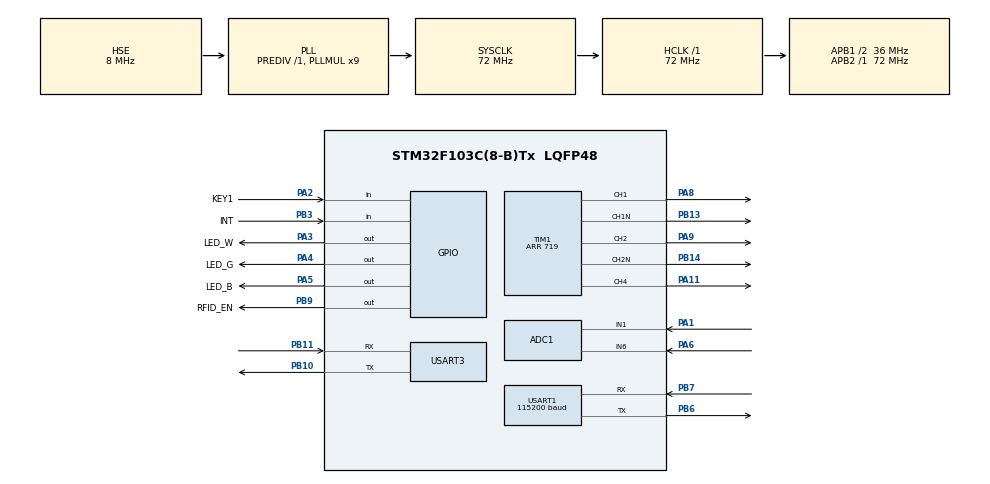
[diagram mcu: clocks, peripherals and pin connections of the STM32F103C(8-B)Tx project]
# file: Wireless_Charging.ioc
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ADC1.Channel-0\#ChannelRegularConversion=ADC_CHANNEL_1
ADC1.Channel-1\#ChannelRegularConversion=ADC_CHANNEL_6
ADC1.ContinuousConvMode=ENABLE
ADC1.NbrOfConversion=2
ADC1.NbrOfConversionFlag=1
ADC1.Rank-0\#ChannelRegularConversion=1
ADC1.Rank-1\#ChannelRegularConversion=2
ADC1.SamplingTime-0\#ChannelRegularConversion=ADC_SAMPLETIME_71CYCLES_5
ADC1.SamplingTime-1\#ChannelRegularConversion=ADC_SAMPLETIME_239CYCLES_5
ADC1.master=1
Dma.ADC1.4.Direction=DMA_PERIPH_TO_MEMORY
Dma.ADC1.4.Instance=DMA1_Channel1
Dma.ADC1.4.MemDataAlignment=DMA_MDATAALIGN_HALFWORD
Dma.ADC1.4.MemInc=DMA_MINC_ENABLE
Dma.ADC1.4.Mode=DMA_CIRCULAR
Dma.ADC1.4.PeriphDataAlignment=DMA_PDATAALIGN_HALFWORD
Dma.ADC1.4.PeriphInc=DMA_PINC_DISABLE
Dma.ADC1.4.Priority=DMA_PRIORITY_HIGH
Dma.Request0=USART1_RX
Dma.Request1=USART1_TX
Dma.Request2=USART3_TX
Dma.Request3=USART3_RX
Dma.Request4=ADC1
Dma.USART1_RX.0.Direction=DMA_PERIPH_TO_MEMORY
Dma.USART1_RX.0.Instance=DMA1_Channel5
Dma.USART1_RX.0.MemDataAlignment=DMA_MDATAALIGN_BYTE
Dma.USART1_RX.0.MemInc=DMA_MINC_ENABLE
Dma.USART1_RX.0.Mode=DMA_CIRCULAR
Dma.USART1_RX.0.PeriphDataAlignment=DMA_PDATAALIGN_BYTE
Dma.USART1_RX.0.PeriphInc=DMA_PINC_DISABLE
Dma.USART1_RX.0.Priority=DMA_PRIORITY_LOW
Dma.USART1_TX.1.Direction=DMA_MEMORY_TO_PERIPH
Dma.USART1_TX.1.Instance=DMA1_Channel4
Dma.USART1_TX.1.MemDataAlignment=DMA_MDATAALIGN_BYTE
Dma.USART1_TX.1.MemInc=DMA_MINC_ENABLE
Dma.USART1_TX.1.Mode=DMA_NORMAL
Dma.USART1_TX.1.PeriphDataAlignment=DMA_PDATAALIGN_BYTE
Dma.USART1_TX.1.PeriphInc=DMA_PINC_DISABLE
Dma.USART1_TX.1.Priority=DMA_PRIORITY_LOW
Dma.USART3_RX.3.Direction=DMA_PERIPH_TO_MEMORY
Dma.USART3_RX.3.Instance=DMA1_Channel3
Dma.USART3_RX.3.MemDataAlignment=DMA_MDATAALIGN_BYTE
Dma.USART3_RX.3.MemInc=DMA_MINC_ENABLE
Dma.USART3_RX.3.Mode=DMA_CIRCULAR
Dma.USART3_RX.3.PeriphDataAlignment=DMA_PDATAALIGN_BYTE
Dma.USART3_RX.3.PeriphInc=DMA_PINC_DISABLE
Dma.USART3_RX.3.Priority=DMA_PRIORITY_LOW
Dma.USART3_TX.2.Direction=DMA_MEMORY_TO_PERIPH
Dma.USART3_TX.2.Instance=DMA1_Channel2
Dma.USART3_TX.2.MemDataAlignment=DMA_MDATAALIGN_BYTE
Dma.USART3_TX.2.MemInc=DMA_MINC_ENABLE
Dma.USART3_TX.2.Mode=DMA_NORMAL
Dma.USART3_TX.2.PeriphDataAlignment=DMA_PDATAALIGN_BYTE
Dma.USART3_TX.2.PeriphInc=DMA_PINC_DISABLE
Dma.USART3_TX.2.Priority=DMA_PRIORITY_LOW
FREERTOS.Events01=xDataProcessEvent,Dynamic,NULL
FREERTOS.INCLUDE_xEventGroupSetBitFromISR=1
FREERTOS.Tasks01=defaultTask,8,64,StartDefaultTask,Default,NULL,Dynamic,NULL,NULL;controlTask,32,256,StartControlTask,As external,NULL,Dynamic,NULL,NULL;dataProcessTask,40,256,StartDataProcessTask,As external,NULL,Dynamic,NULL,NULL
FREERTOS.configENABLE_FPU=0
FREERTOS.configMINIMAL_STACK_SIZE=64
Mcu.Family=STM32F1
Mcu.Name=STM32F103C(8-B)Tx
Mcu.Package=LQFP48
NVIC.DMA1_Channel1_IRQn=true\:5\:0\:false\:false\:true\:true\:false\:true\:true
NVIC.DMA1_Channel2_IRQn=true\:5\:0\:false\:false\:true\:true\:false\:true\:true
NVIC.DMA1_Channel3_IRQn=true\:5\:0\:false\:false\:true\:true\:false\:true\:true
NVIC.DMA1_Channel4_IRQn=true\:5\:0\:false\:false\:true\:true\:false\:true\:true
NVIC.DMA1_Channel5_IRQn=true\:5\:0\:false\:false\:true\:true\:false\:true\:true
NVIC.PriorityGroup=NVIC_PRIORITYGROUP_4
NVIC.TIM2_IRQn=true\:15\:0\:false\:false\:true\:false\:false\:true\:true
NVIC.TIM3_IRQn=true\:5\:0\:false\:false\:true\:true\:true\:true\:true
NVIC.TIM4_IRQn=true\:5\:0\:false\:false\:true\:true\:true\:true\:true
NVIC.TimeBase=TIM2_IRQn
NVIC.TimeBaseIP=TIM2
NVIC.USART1_IRQn=true\:5\:0\:false\:false\:true\:true\:true\:true\:true
NVIC.USART3_IRQn=true\:5\:0\:false\:false\:true\:true\:true\:true\:true
PA1.Signal=ADCx_IN1
PA11.Signal=S_TIM1_CH4
PA13.Mode=Serial_Wire
PA13.Signal=SYS_JTMS-SWDIO
PA14.Mode=Serial_Wire
PA14.Signal=SYS_JTCK-SWCLK
PA2.GPIO_Label=KEY1
PA2.Signal=GPIO_Input
PA3.GPIO_Label=LED_W
PA3.Signal=GPIO_Output
PA4.GPIO_Label=LED_G
PA4.Signal=GPIO_Output
PA5.GPIO_Label=LED_B
PA5.Signal=GPIO_Output
PA6.Signal=ADCx_IN6
PA8.GPIO_Speed=GPIO_SPEED_FREQ_HIGH
PA8.Signal=S_TIM1_CH1
PA9.GPIO_Speed=GPIO_SPEED_FREQ_HIGH
PA9.Signal=S_TIM1_CH2
PB10.Mode=Asynchronous
PB10.Signal=USART3_TX
PB11.Mode=Asynchronous
PB11.Signal=USART3_RX
PB13.Mode=PWM Generation1 CH1 CH1N
PB13.Signal=TIM1_CH1N
PB14.Mode=PWM Generation2 CH2 CH2N
PB14.Signal=TIM1_CH2N
PB3.GPIO_Label=INT
PB3.Signal=GPIO_Input
PB6.Mode=Asynchronous
PB6.Signal=USART1_TX
PB7.Mode=Asynchronous
PB7.Signal=USART1_RX
PB9.GPIO_Label=RFID_EN
PB9.Signal=GPIO_Output
PD0-OSC_IN.Mode=HSE-External-Oscillator
PD0-OSC_IN.Signal=RCC_OSC_IN
PD1-OSC_OUT.Mode=HSE-External-Oscillator
PD1-OSC_OUT.Signal=RCC_OSC_OUT
ProjectManager.HeapSize=0x200
ProjectManager.StackSize=0x400
ProjectManager.TargetToolchain=MDK-ARM V5.32
RCC.ADCPresc=RCC_ADCPCLK2_DIV6
RCC.AHBFreq_Value=72000000
RCC.APB1CLKDivider=RCC_HCLK_DIV2
RCC.APB1Freq_Value=36000000
RCC.APB1TimFreq_Value=72000000
RCC.APB2Freq_Value=72000000
RCC.APB2TimFreq_Value=72000000
RCC.HCLKFreq_Value=72000000
RCC.PLLMUL=RCC_PLL_MUL9
RCC.PLLSourceVirtual=RCC_PLLSOURCE_HSE
RCC.SYSCLKFreq_VALUE=72000000
RCC.SYSCLKSource=RCC_SYSCLKSOURCE_PLLCLK
RCC.USBFreq_Value=72000000
SH.ADCx_IN1.0=ADC1_IN1,IN1
SH.ADCx_IN6.0=ADC1_IN6,IN6
SH.S_TIM1_CH1.0=TIM1_CH1,PWM Generation1 CH1 CH1N
SH.S_TIM1_CH2.0=TIM1_CH2,PWM Generation2 CH2 CH2N
SH.S_TIM1_CH4.0=TIM1_CH4,PWM Generation4 CH4
TIM1.AutoReloadPreload=TIM_AUTORELOAD_PRELOAD_ENABLE
TIM1.Channel-PWM\ Generation1\ CH1\ CH1N=TIM_CHANNEL_1
TIM1.Channel-PWM\ Generation2\ CH2\ CH2N=TIM_CHANNEL_2
TIM1.Channel-PWM\ Generation4\ CH4=TIM_CHANNEL_4
TIM1.DeadTime=14
TIM1.Period=719
TIM1.Pulse-PWM\ Generation1\ CH1\ CH1N=359
TIM1.Pulse-PWM\ Generation2\ CH2\ CH2N=359
TIM1.Pulse-PWM\ Generation4\ CH4=300
TIM3.AutoReloadPreload=TIM_AUTORELOAD_PRELOAD_ENABLE
TIM3.Period=99
TIM3.Prescaler=7199
TIM4.AutoReloadPreload=TIM_AUTORELOAD_PRELOAD_ENABLE
TIM4.Period=99
TIM4.Prescaler=287
USART1.BaudRate=115200
USART1.VirtualMode=VM_ASYNC
USART3.VirtualMode=VM_ASYNC
VP_FREERTOS_VS_CMSIS_V2.Mode=CMSIS_V2
VP_SYS_VS_tim2.Mode=TIM2
VP_TIM1_VS_ClockSourceINT.Mode=Internal
VP_TIM3_VS_ClockSourceINT.Mode=Internal
VP_TIM4_VS_ClockSourceINT.Mode=Internal
board=custom

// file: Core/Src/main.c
/* USER CODE BEGIN Header */
/**
  ******************************************************************************
  * @file           : main.c
  * @brief          : Main program body
  ******************************************************************************
  * @attention
  *
  * Copyright (c) 2025 STMicroelectronics.
  * All rights reserved.
  *
  * This software is licensed under terms that can be found in the LICENSE file
  * in the root directory of this software component.
  * If no LICENSE file comes with this software, it is provided AS-IS.
  *
  ******************************************************************************
  */
/* USER CODE END Header */
#include "main.h"
#include "cmsis_os.h"
#include "adc.h"
#include "dma.h"
#include "tim.h"
#include "usart.h"
#include "gpio.h"

/* USER CODE BEGIN Includes */
#include "device.h"
#include "driver.h"
/* USER CODE END Includes */

void SystemClock_Config(void);
void MX_FREERTOS_Init(void);

int main(void)
{

  /* MCU Configuration--------------------------------------------------------*/

  /* Reset of all peripherals, Initializes the Flash interface and the Systick. */
  HAL_Init();

  /* Configure the system clock */
  SystemClock_Config();

  /* Initialize all configured peripherals */
  MX_GPIO_Init();
  MX_DMA_Init();
  MX_TIM1_Init();
  MX_USART1_UART_Init();
  MX_USART3_UART_Init();
  MX_ADC1_Init();
  MX_TIM3_Init();
  MX_TIM4_Init();
  /* USER CODE BEGIN 2 */

  /* Initialize the driver */
  Driver_Init();
  /* Initialize the device */
  Device_Init();

  /* USER CODE END 2 */

  /* Init scheduler */
  osKernelInitialize();  /* Call init function for freertos objects (in cmsis_os2.c) */
  MX_FREERTOS_Init();

  /* Start scheduler */
  osKernelStart();

  /* We should never get here as control is now taken by the scheduler */

  /* Infinite loop */
  while (1)
  {

  }
}

void SystemClock_Config(void)
{
  RCC_OscInitTypeDef RCC_OscInitStruct = {0};
  RCC_ClkInitTypeDef RCC_ClkInitStruct = {0};
  RCC_PeriphCLKInitTypeDef PeriphClkInit = {0};

  /** Initializes the RCC Oscillators according to the specified parameters
  * in the RCC_OscInitTypeDef structure.
  */
  RCC_OscInitStruct.OscillatorType = RCC_OSCILLATORTYPE_HSE;
  RCC_OscInitStruct.HSEState = RCC_HSE_ON;
  RCC_OscInitStruct.HSEPredivValue = RCC_HSE_PREDIV_DIV1;
  RCC_OscInitStruct.HSIState = RCC_HSI_ON;
  RCC_OscInitStruct.PLL.PLLState = RCC_PLL_ON;
  RCC_OscInitStruct.PLL.PLLSource = RCC_PLLSOURCE_HSE;
  RCC_OscInitStruct.PLL.PLLMUL = RCC_PLL_MUL9;
  if (HAL_RCC_OscConfig(&RCC_OscInitStruct) != HAL_OK)
  {
    Error_Handler();
  }

  /** Initializes the CPU, AHB and APB buses clocks
  */
  RCC_ClkInitStruct.ClockType = RCC_CLOCKTYPE_HCLK|RCC_CLOCKTYPE_SYSCLK
                              |RCC_CLOCKTYPE_PCLK1|RCC_CLOCKTYPE_PCLK2;
  RCC_ClkInitStruct.SYSCLKSource = RCC_SYSCLKSOURCE_PLLCLK;
  RCC_ClkInitStruct.AHBCLKDivider = RCC_SYSCLK_DIV1;
  RCC_ClkInitStruct.APB1CLKDivider = RCC_HCLK_DIV2;
  RCC_ClkInitStruct.APB2CLKDivider = RCC_HCLK_DIV1;

  if (HAL_RCC_ClockConfig(&RCC_ClkInitStruct, FLASH_LATENCY_2) != HAL_OK)
  {
    Error_Handler();
  }
  PeriphClkInit.PeriphClockSelection = RCC_PERIPHCLK_ADC;
  PeriphClkInit.AdcClockSelection = RCC_ADCPCLK2_DIV6;
  if (HAL_RCCEx_PeriphCLKConfig(&PeriphClkInit) != HAL_OK)
  {
    Error_Handler();
  }
}

void HAL_TIM_PeriodElapsedCallback(TIM_HandleTypeDef *htim)
{
  if (htim->Instance == TIM2)
  {
    HAL_IncTick();
  }
}

void Error_Handler(void)
{
  __disable_irq();
  while (1)
  {
  }
}

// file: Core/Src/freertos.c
/* USER CODE BEGIN Header */
/**
  ******************************************************************************
  * File Name          : freertos.c
  * Description        : Code for freertos applications
  ******************************************************************************
  * @attention
  *
  * Copyright (c) 2025 STMicroelectronics.
  * All rights reserved.
  *
  * This software is licensed under terms that can be found in the LICENSE file
  * in the root directory of this software component.
  * If no LICENSE file comes with this software, it is provided AS-IS.
  *
  ******************************************************************************
  */
/* USER CODE END Header */

#include "FreeRTOS.h"
#include "task.h"
#include "main.h"
#include "cmsis_os.h"

/* Definitions for defaultTask */
osThreadId_t defaultTaskHandle;
const osThreadAttr_t defaultTask_attributes = {
  .name = "defaultTask",
  .stack_size = 64 * 4,
  .priority = (osPriority_t) osPriorityLow,
};
/* Definitions for controlTask */
osThreadId_t controlTaskHandle;
const osThreadAttr_t controlTask_attributes = {
  .name = "controlTask",
  .stack_size = 256 * 4,
  .priority = (osPriority_t) osPriorityAboveNormal,
};
/* Definitions for dataProcessTask */
osThreadId_t dataProcessTaskHandle;
const osThreadAttr_t dataProcessTask_attributes = {
  .name = "dataProcessTask",
  .stack_size = 256 * 4,
  .priority = (osPriority_t) osPriorityHigh,
};
/* Definitions for xDataProcessEvent */
osEventFlagsId_t xDataProcessEventHandle;
const osEventFlagsAttr_t xDataProcessEvent_attributes = {
  .name = "xDataProcessEvent"
};

void StartDefaultTask(void *argument);
extern void StartControlTask(void *argument);
extern void StartDataProcessTask(void *argument);

void MX_FREERTOS_Init(void); /* (MISRA C 2004 rule 8.1) */

void MX_FREERTOS_Init(void) {

  /* Create the thread(s) */
  /* creation of defaultTask */
  defaultTaskHandle = osThreadNew(StartDefaultTask, NULL, &defaultTask_attributes);

  /* creation of controlTask */
  controlTaskHandle = osThreadNew(StartControlTask, NULL, &controlTask_attributes);

  /* creation of dataProcessTask */
  dataProcessTaskHandle = osThreadNew(StartDataProcessTask, NULL, &dataProcessTask_attributes);

  /* Create the event(s) */
  /* creation of xDataProcessEvent */
  xDataProcessEventHandle = osEventFlagsNew(&xDataProcessEvent_attributes);

}

void StartDefaultTask(void *argument)
{
  for(;;)
  {
    osDelay(1);
  }
}
